# ESP32 register map
Vendor: ESPRESSIF SYSTEMS (SHANGHAI) CO., LTD.; Series: ESP32 Series; File version: 17
CPU: Xtensa LX6 r0p0, little endian, no MPU, FPU, 0 interrupt priority bits
Address unit: 32 bits
Registers are 32-bit, read-write, reset 0x0 unless marked. A register's access mark holds for its fields unless they carry their own. Offsets are from the block's base; [hi:lo] are bit positions; {n}, {i} and the like mark numbered series.

## SPI0 — SPI (Serial Peripheral Interface) Controller 0
Base 0x3FF43000
Same registers: SPI1 0x3FF42000, SPI2 0x3FF64000, SPI3 0x3FF65000
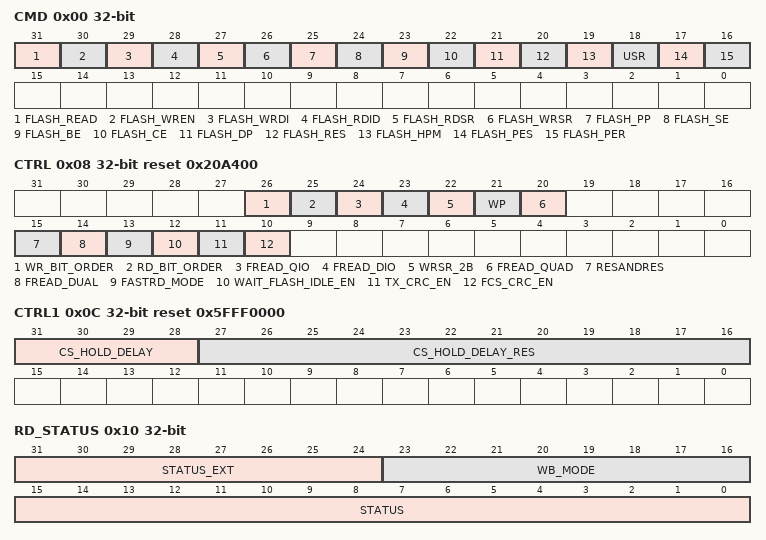
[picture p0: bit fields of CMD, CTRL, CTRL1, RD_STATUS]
0x00 CMD
  [31] FLASH_READ — Read flash enable. Read flash operation will be triggered when the bit is set. The bit will be cleared once the operation done. 1: enable 0: disable.
  [30] FLASH_WREN — Write flash enable. Write enable command will be sent when the bit is set. The bit will be cleared once the operation done. 1: enable 0: disable.
  [29] FLASH_WRDI — Write flash disable. Write disable command will be sent when the bit is set. The bit will be cleared once the operation done. 1: enable 0: disable.
  [28] FLASH_RDID — Read JEDEC ID . Read ID command will be sent when the bit is set. The bit will be cleared once the operation done. 1: enable 0: disable.
  [27] FLASH_RDSR — Read status register-1. Read status operation will be triggered when the bit is set. The bit will be cleared once the operation done.1: enable 0: disable.
  [26] FLASH_WRSR — Write status register enable. Write status operation will be triggered when the bit is set. The bit will be cleared once the operation done.1: enable 0: disable.
  [25] FLASH_PP — Page program enable(1 byte ~256 bytes data to be programmed). Page program operation will be triggered when the bit is set. The bit will be cleared once the operation done .1: enable 0: disable.
  [24] FLASH_SE — Sector erase enable. A 4KB sector is erased via SPI command 20H. Sector erase operation will be triggered when the bit is set. The bit will be cleared once the operation done.1: enable 0: disable.
  [23] FLASH_BE — Block erase enable. A 64KB block is erased via SPI command D8H. Block erase operation will be triggered when the bit is set. The bit will be cleared once the operation done.1: enable 0: disable.
  [22] FLASH_CE — Chip erase enable. Chip erase operation will be triggered when the bit is set. The bit will be cleared once the operation done.1: enable 0: disable.
  [21] FLASH_DP — Drive Flash into power down. An operation will be triggered when the bit is set. The bit will be cleared once the operation done.1: enable 0: disable.
  [20] FLASH_RES — This bit combined with reg_resandres bit releases Flash from the power-down state or high performance mode and obtains the devices ID. The bit will be cleared once the operation done.1: enable 0: disable.
  [19] FLASH_HPM — Drive Flash into high performance mode. The bit will be cleared once the operation done.1: enable 0: disable.
  [18] USR — User define command enable. An operation will be triggered when the bit is set. The bit will be cleared once the operation done.1: enable 0: disable.
  [17] FLASH_PES — program erase suspend bit program erase suspend operation will be triggered when the bit is set. The bit will be cleared once the operation done.1: enable 0: disable.
  [16] FLASH_PER — program erase resume bit program erase suspend operation will be triggered when the bit is set. The bit will be cleared once the operation done.1: enable 0: disable.
0x04 ADDR access not given
0x08 CTRL reset 0x20A400
  [26] WR_BIT_ORDER — In command address write-data (MOSI) phases 1: LSB firs 0: MSB first
  [25] RD_BIT_ORDER — In read-data (MISO) phase 1: LSB first 0: MSB first
  [24] FREAD_QIO — In the read operations address phase and read-data phase apply 4 signals. 1: enable 0: disable.
  [23] FREAD_DIO — In the read operations address phase and read-data phase apply 2 signals. 1: enable 0: disable.
  [22] WRSR_2B — two bytes data will be written to status register when it is set. 1: enable 0: disable.
  [21] WP — Write protect signal output when SPI is idle. 1: output high 0: output low.
  [20] FREAD_QUAD — In the read operations read-data phase apply 4 signals. 1: enable 0: disable.
  [15] RESANDRES — The Device ID is read out to SPI_RD_STATUS register, this bit combine with spi_flash_res bit. 1: enable 0: disable.
  [14] FREAD_DUAL — In the read operations read-data phase apply 2 signals. 1: enable 0: disable.
  [13] FASTRD_MODE — This bit enable the bits: spi_fread_qio spi_fread_dio spi_fread_qout and spi_fread_dout. 1: enable 0: disable.
  [12] WAIT_FLASH_IDLE_EN — wait flash idle when program flash or erase flash. 1: enable 0: disable.
  [11] TX_CRC_EN — For SPI1 enable crc32 when writing encrypted data to flash. 1: enable 0:disable
  [10] FCS_CRC_EN — For SPI1 initialize crc32 module before writing encrypted data to flash. Active low.
0x0C CTRL1 reset 0x5FFF0000
  [31:28] CS_HOLD_DELAY — SPI cs signal is delayed by spi clock cycles
  [27:16] CS_HOLD_DELAY_RES — Delay cycles of resume Flash when resume Flash is enable by spi clock.
0x10 RD_STATUS
  [31:24] STATUS_EXT — In the slave mode,it is the status for master to read out.
  [23:16] WB_MODE — Mode bits in the flash fast read mode, it is combined with spi_fastrd_mode bit.
  [15:0] STATUS — In the slave mode, it is the status for master to read out.
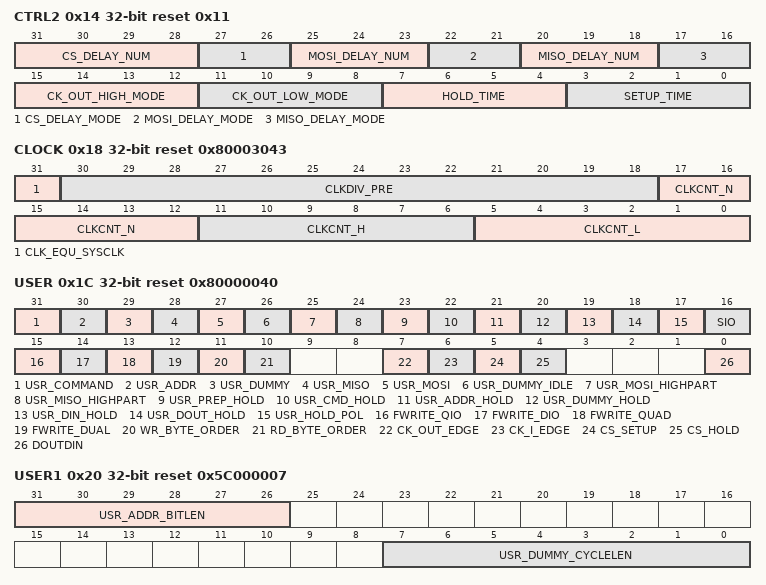
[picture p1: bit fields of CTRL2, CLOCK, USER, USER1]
0x14 CTRL2 reset 0x11
  [31:28] CS_DELAY_NUM — spi_cs signal is delayed by system clock cycles
  [27:26] CS_DELAY_MODE — spi_cs signal is delayed by spi_clk . 0: zero 1: if spi_ck_out_edge or spi_ck_i_edge is set 1 delayed by half cycle else delayed by one cycle 2: if spi_ck_out_edge or spi_ck_i_edge is set 1 delayed by one cycle else delayed by half cycle 3: delayed one cycle
  [25:23] MOSI_DELAY_NUM — MOSI signals are delayed by system clock cycles
  [22:21] MOSI_DELAY_MODE — MOSI signals are delayed by spi_clk. 0: zero 1: if spi_ck_out_edge or spi_ck_i_edge is set 1 delayed by half cycle else delayed by one cycle 2: if spi_ck_out_edge or spi_ck_i_edge is set 1 delayed by one cycle else delayed by half cycle 3: delayed one cycle
  [20:18] MISO_DELAY_NUM — MISO signals are delayed by system clock cycles
  [17:16] MISO_DELAY_MODE — MISO signals are delayed by spi_clk. 0: zero 1: if spi_ck_out_edge or spi_ck_i_edge is set 1 delayed by half cycle else delayed by one cycle 2: if spi_ck_out_edge or spi_ck_i_edge is set 1 delayed by one cycle else delayed by half cycle 3: delayed one cycle
  [15:12] CK_OUT_HIGH_MODE — modify spi clock duty ratio when the value is lager than 8, the bits are combined with spi_clkcnt_N bits and spi_clkcnt_H bits.
  [11:8] CK_OUT_LOW_MODE — modify spi clock duty ratio when the value is lager than 8, the bits are combined with spi_clkcnt_N bits and spi_clkcnt_L bits.
  [7:4] HOLD_TIME — delay cycles of cs pin by spi clock, this bits combined with spi_cs_hold bit.
  [3:0] SETUP_TIME — (cycles-1) of ¡°prepare¡± phase by spi clock, this bits combined with spi_cs_setup bit.
0x18 CLOCK reset 0x80003043
  [31] CLK_EQU_SYSCLK — In the master mode 1: spi_clk is eqaul to system 0: spi_clk is divided from system clock.
  [30:18] CLKDIV_PRE — In the master mode it is pre-divider of spi_clk.
  [17:12] CLKCNT_N — In the master mode it is the divider of spi_clk. So spi_clk frequency is system/(spi_clkdiv_pre+1)/(spi_clkcnt_N+1)
  [11:6] CLKCNT_H — In the master mode it must be floor((spi_clkcnt_N+1)/2-1). In the slave mode it must be 0.
  [5:0] CLKCNT_L — In the master mode it must be equal to spi_clkcnt_N. In the slave mode it must be 0.
0x1C USER reset 0x80000040
  [31] USR_COMMAND — This bit enable the command phase of an operation.
  [30] USR_ADDR — This bit enable the address phase of an operation.
  [29] USR_DUMMY — This bit enable the dummy phase of an operation.
  [28] USR_MISO — This bit enable the read-data phase of an operation.
  [27] USR_MOSI — This bit enable the write-data phase of an operation.
  [26] USR_DUMMY_IDLE — spi clock is disable in dummy phase when the bit is enable.
  [25] USR_MOSI_HIGHPART — write-data phase only access to high-part of the buffer spi_w8~spi_w15. 1: enable 0: disable.
  [24] USR_MISO_HIGHPART — read-data phase only access to high-part of the buffer spi_w8~spi_w15. 1: enable 0: disable.
  [23] USR_PREP_HOLD — spi is hold at prepare state the bit combined with spi_usr_hold_pol bit.
  [22] USR_CMD_HOLD — spi is hold at command state the bit combined with spi_usr_hold_pol bit.
  [21] USR_ADDR_HOLD — spi is hold at address state the bit combined with spi_usr_hold_pol bit.
  [20] USR_DUMMY_HOLD — spi is hold at dummy state the bit combined with spi_usr_hold_pol bit.
  [19] USR_DIN_HOLD — spi is hold at data in state the bit combined with spi_usr_hold_pol bit.
  [18] USR_DOUT_HOLD — spi is hold at data out state the bit combined with spi_usr_hold_pol bit.
  [17] USR_HOLD_POL — It is combined with hold bits to set the polarity of spi hold line 1: spi will be held when spi hold line is high 0: spi will be held when spi hold line is low
  [16] SIO — Set the bit to enable 3-line half duplex communication mosi and miso signals share the same pin. 1: enable 0: disable.
  [15] FWRITE_QIO — In the write operations address phase and read-data phase apply 4 signals.
  [14] FWRITE_DIO — In the write operations address phase and read-data phase apply 2 signals.
  [13] FWRITE_QUAD — In the write operations read-data phase apply 4 signals
  [12] FWRITE_DUAL — In the write operations read-data phase apply 2 signals
  [11] WR_BYTE_ORDER — In command address write-data (MOSI) phases 1: big-endian 0: litte_endian
  [10] RD_BYTE_ORDER — In read-data (MISO) phase 1: big-endian 0: little_endian
  [7] CK_OUT_EDGE — the bit combined with spi_mosi_delay_mode bits to set mosi signal delay mode.
  [6] CK_I_EDGE — In the slave mode the bit is same as spi_ck_out_edge in master mode. It is combined with spi_miso_delay_mode bits.
  [5] CS_SETUP — spi cs is enable when spi is in ¡°prepare¡± phase. 1: enable 0: disable.
  [4] CS_HOLD — spi cs keep low when spi is in ¡°done¡± phase. 1: enable 0: disable.
  [0] DOUTDIN — Set the bit to enable full duplex communication. 1: enable 0: disable.
0x20 USER1 reset 0x5C000007
  [31:26] USR_ADDR_BITLEN — The length in bits of address phase. The register value shall be (bit_num-1).
  [7:0] USR_DUMMY_CYCLELEN — The length in spi_clk cycles of dummy phase. The register value shall be (cycle_num-1).
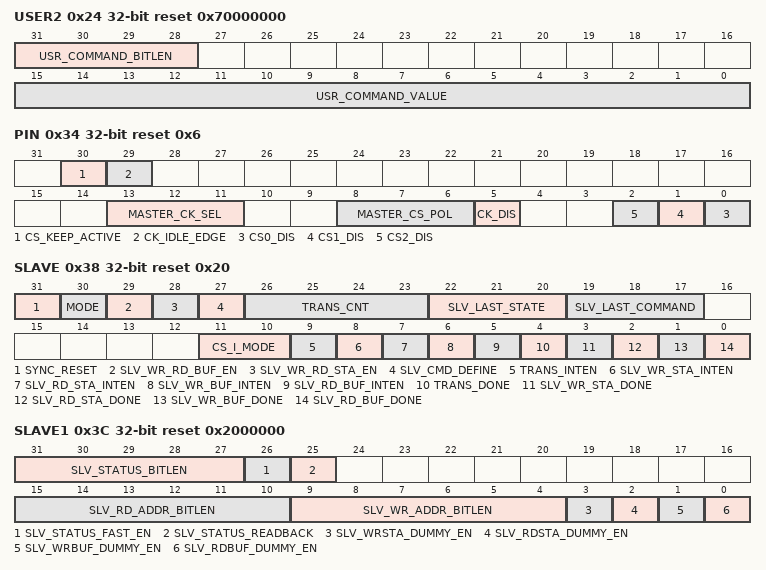
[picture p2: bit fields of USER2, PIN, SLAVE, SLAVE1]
0x24 USER2 reset 0x70000000
  [31:28] USR_COMMAND_BITLEN — The length in bits of command phase. The register value shall be (bit_num-1)
  [15:0] USR_COMMAND_VALUE — The value of command.
0x28 MOSI_DLEN
  [23:0] USR_MOSI_DBITLEN — The length in bits of write-data. The register value shall be (bit_num-1).
0x2C MISO_DLEN
  [23:0] USR_MISO_DBITLEN — The length in bits of read-data. The register value shall be (bit_num-1).
0x30 SLV_WR_STATUS
  [31:0] SLV_WR_ST — In the slave mode this register are the status register for the master to write into. In the master mode this register are the higher 32bits in the 64 bits address condition.
0x34 PIN reset 0x6
  [30] CS_KEEP_ACTIVE — spi cs line keep low when the bit is set.
  [29] CK_IDLE_EDGE — 1: spi clk line is high when idle 0: spi clk line is low when idle
  [13:11] MASTER_CK_SEL — In the master mode spi cs line is enable as spi clk it is combined with spi_cs0_dis spi_cs1_dis spi_cs2_dis.
  [8:6] MASTER_CS_POL — In the master mode the bits are the polarity of spi cs line the value is equivalent to spi_cs ^ spi_master_cs_pol.
  [5] CK_DIS — 1: spi clk out disable 0: spi clk out enable
  [n] CS{n}_DIS (n=0..2) — Set this bit to raise high SPI_CS{n} pin, which means that the SPI device(Ext_RAM(0)/flash(1)) connected to SPI_CS{n} is in low level when SPI1 transfer starts
0x38 SLAVE access not given reset 0x20
  [31] SYNC_RESET rw — Software reset enable, reset the spi clock line cs line and data lines.
  [30] MODE rw — 1: slave mode 0: master mode.
  [29] SLV_WR_RD_BUF_EN rw — write and read buffer enable in the slave mode
  [28] SLV_WR_RD_STA_EN rw — write and read status enable in the slave mode
  [27] SLV_CMD_DEFINE rw — 1: slave mode commands are defined in SPI_SLAVE3. 0: slave mode commands are fixed as: 1: write-status 2: write-buffer and 3: read-buffer.
  [26:23] TRANS_CNT ro — The operations counter in both the master mode and the slave mode. 4: read-status
  [22:20] SLV_LAST_STATE ro — In the slave mode it is the state of spi state machine.
  [19:17] SLV_LAST_COMMAND ro — In the slave mode it is the value of command.
  [11:10] CS_I_MODE rw — In the slave mode this bits used to synchronize the input spi cs signal and eliminate spi cs jitter.
  [9] TRANS_INTEN — The interrupt enable bit for the SPI_TRANS_DONE_INT interrupt.
  [8] SLV_WR_STA_INTEN — The interrupt enable bit for the SPI_SLV_WR_STA_INT interrupt.
  [7] SLV_RD_STA_INTEN — The interrupt enable bit for the SPI_SLV_RD_STA_INT interrupt.
  [6] SLV_WR_BUF_INTEN — The interrupt enable bit for the SPI_SLV_WR_BUF_INT interrupt.
  [5] SLV_RD_BUF_INTEN — The interrupt enable bit for the SPI_SLV_RD_BUF_INT interrupt.
  [4] TRANS_DONE rw — The interrupt raw bit for the completion of any operation in both the master mode and the slave mode.
  [3] SLV_WR_STA_DONE rw — The interrupt raw bit for the completion of write-status operation in the slave mode.
  [2] SLV_RD_STA_DONE rw — The interrupt raw bit for the completion of read-status operation in the slave mode.
  [1] SLV_WR_BUF_DONE rw — The interrupt raw bit for the completion of write-buffer operation in the slave mode.
  [0] SLV_RD_BUF_DONE rw — The interrupt raw bit for the completion of read-buffer operation in the slave mode.
0x3C SLAVE1 reset 0x2000000
  [31:27] SLV_STATUS_BITLEN — In the slave mode it is the length of status bit.
  [26] SLV_STATUS_FAST_EN — In the slave mode enable fast read status.
  [25] SLV_STATUS_READBACK — In the slave mode 1:read register of SPI_SLV_WR_STATUS 0: read register of SPI_RD_STATUS.
  [15:10] SLV_RD_ADDR_BITLEN — In the slave mode it is the address length in bits for read-buffer operation. The register value shall be (bit_num-1).
  [9:4] SLV_WR_ADDR_BITLEN — In the slave mode it is the address length in bits for write-buffer operation. The register value shall be (bit_num-1).
  [3] SLV_WRSTA_DUMMY_EN — In the slave mode it is the enable bit of dummy phase for write-status operations.
  [2] SLV_RDSTA_DUMMY_EN — In the slave mode it is the enable bit of dummy phase for read-status operations.
  [1] SLV_WRBUF_DUMMY_EN — In the slave mode it is the enable bit of dummy phase for write-buffer operations.
  [0] SLV_RDBUF_DUMMY_EN — In the slave mode it is the enable bit of dummy phase for read-buffer operations.
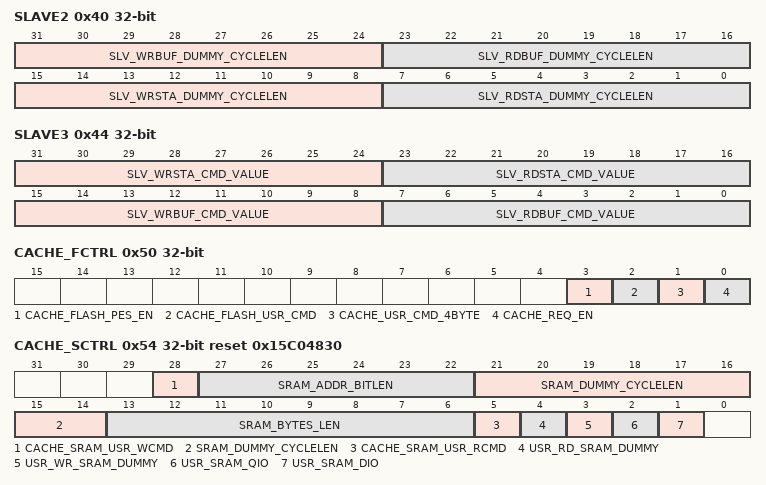
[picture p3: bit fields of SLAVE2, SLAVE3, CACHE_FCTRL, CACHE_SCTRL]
0x40 SLAVE2
  [31:24] SLV_WRBUF_DUMMY_CYCLELEN — In the slave mode it is the length in spi_clk cycles of dummy phase for write-buffer operations. The register value shall be (cycle_num-1).
  [23:16] SLV_RDBUF_DUMMY_CYCLELEN — In the slave mode it is the length in spi_clk cycles of dummy phase for read-buffer operations. The register value shall be (cycle_num-1).
  [15:8] SLV_WRSTA_DUMMY_CYCLELEN — In the slave mode it is the length in spi_clk cycles of dummy phase for write-status operations. The register value shall be (cycle_num-1).
  [7:0] SLV_RDSTA_DUMMY_CYCLELEN — In the slave mode it is the length in spi_clk cycles of dummy phase for read-status operations. The register value shall be (cycle_num-1).
0x44 SLAVE3
  [31:24] SLV_WRSTA_CMD_VALUE — In the slave mode it is the value of write-status command.
  [23:16] SLV_RDSTA_CMD_VALUE — In the slave mode it is the value of read-status command.
  [15:8] SLV_WRBUF_CMD_VALUE — In the slave mode it is the value of write-buffer command.
  [7:0] SLV_RDBUF_CMD_VALUE — In the slave mode it is the value of read-buffer command.
0x48 SLV_WRBUF_DLEN
  [23:0] SLV_WRBUF_DBITLEN — In the slave mode it is the length in bits for write-buffer operations. The register value shall be (bit_num-1).
0x4C SLV_RDBUF_DLEN
  [23:0] SLV_RDBUF_DBITLEN — In the slave mode it is the length in bits for read-buffer operations. The register value shall be (bit_num-1).
0x50 CACHE_FCTRL
  [3] CACHE_FLASH_PES_EN — For SPI0 spi1 send suspend command before cache read flash 1: enable 0:disable.
  [2] CACHE_FLASH_USR_CMD — For SPI0 cache read flash for user define command 1: enable 0:disable.
  [1] CACHE_USR_CMD_4BYTE — For SPI0 cache read flash with 4 bytes command 1: enable 0:disable.
  [0] CACHE_REQ_EN — For SPI0 Cache access enable 1: enable 0:disable.
0x54 CACHE_SCTRL reset 0x15C04830
  [28] CACHE_SRAM_USR_WCMD — For SPI0 In the spi sram mode cache write sram for user define command
  [27:22] SRAM_ADDR_BITLEN — For SPI0 In the sram mode it is the length in bits of address phase. The register value shall be (bit_num-1).
  [21:14] SRAM_DUMMY_CYCLELEN — For SPI0 In the sram mode it is the length in bits of address phase. The register value shall be (bit_num-1).
  [13:6] SRAM_BYTES_LEN — For SPI0 In the sram mode it is the byte length of spi read sram data.
  [5] CACHE_SRAM_USR_RCMD — For SPI0 In the spi sram mode cache read sram for user define command.
  [4] USR_RD_SRAM_DUMMY — For SPI0 In the spi sram mode it is the enable bit of dummy phase for read operations.
  [3] USR_WR_SRAM_DUMMY — For SPI0 In the spi sram mode it is the enable bit of dummy phase for write operations.
  [2] USR_SRAM_QIO — For SPI0 In the spi sram mode spi quad I/O mode enable 1: enable 0:disable
  [1] USR_SRAM_DIO — For SPI0 In the spi sram mode spi dual I/O mode enable 1: enable 0:disable
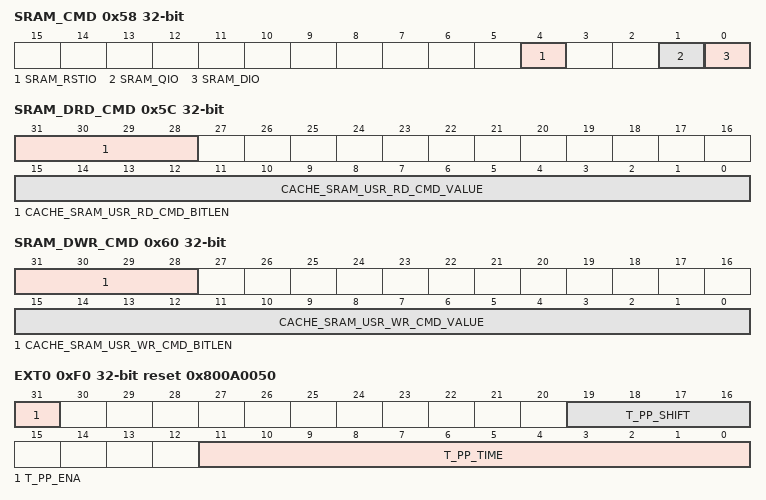
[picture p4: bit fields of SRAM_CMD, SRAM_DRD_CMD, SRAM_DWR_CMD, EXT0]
0x58 SRAM_CMD
  [4] SRAM_RSTIO — For SPI0 SRAM IO mode reset enable. SRAM IO mode reset operation will be triggered when the bit is set. The bit will be cleared once the operation done
  [1] SRAM_QIO — For SPI0 SRAM QIO mode enable . SRAM QIO enable command will be send when the bit is set. The bit will be cleared once the operation done.
  [0] SRAM_DIO — For SPI0 SRAM DIO mode enable . SRAM DIO enable command will be send when the bit is set. The bit will be cleared once the operation done.
0x5C SRAM_DRD_CMD
  [31:28] CACHE_SRAM_USR_RD_CMD_BITLEN — For SPI0 When cache mode is enable it is the length in bits of command phase for SRAM. The register value shall be (bit_num-1).
  [15:0] CACHE_SRAM_USR_RD_CMD_VALUE — For SPI0 When cache mode is enable it is the read command value of command phase for SRAM.
0x60 SRAM_DWR_CMD
  [31:28] CACHE_SRAM_USR_WR_CMD_BITLEN — For SPI0 When cache mode is enable it is the in bits of command phase for SRAM. The register value shall be (bit_num-1).
  [15:0] CACHE_SRAM_USR_WR_CMD_VALUE — For SPI0 When cache mode is enable it is the write command value of command phase for SRAM.
0x64 SLV_RD_BIT
  [23:0] SLV_RDATA_BIT — In the slave mode it is the bit length of read data. The value is the length - 1.
{0x80+4i} W{i} (i=0..15)
  [31:0] BUF — data buffer
0xC0 TX_CRC
  [31:0] DATA — For SPI1 the value of crc32 for 256 bits data.
0xF0 EXT0 reset 0x800A0050
  [31] T_PP_ENA — page program delay enable.
  [19:16] T_PP_SHIFT — page program delay time shift .
  [11:0] T_PP_TIME — page program delay time by system clock.
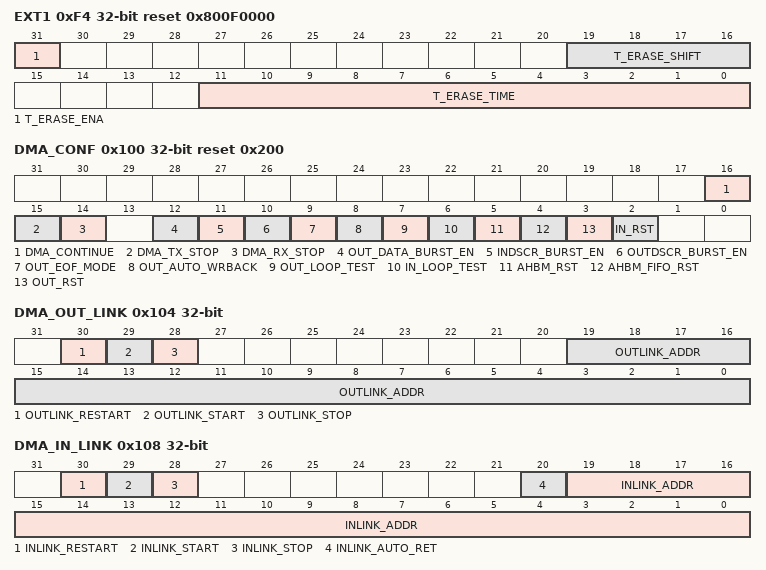
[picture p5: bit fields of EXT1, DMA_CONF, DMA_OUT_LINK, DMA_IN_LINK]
0xF4 EXT1 reset 0x800F0000
  [31] T_ERASE_ENA — erase flash delay enable.
  [19:16] T_ERASE_SHIFT — erase flash delay time shift.
  [11:0] T_ERASE_TIME — erase flash delay time by system clock.
0xF8 EXT2 ro
  [2:0] ST — The status of spi state machine .
0xFC EXT3
  [1:0] INT_HOLD_ENA — This register is for two SPI masters to share the same cs clock and data signals. The bits of one SPI are set if the other SPI is busy the SPI will be hold. 1(3): hold at ¡°idle¡± phase 2: hold at ¡°prepare¡± phase.
0x100 DMA_CONF reset 0x200
  [16] DMA_CONTINUE — spi dma continue tx/rx data.
  [15] DMA_TX_STOP — spi dma write data stop when in continue tx/rx mode.
  [14] DMA_RX_STOP — spi dma read data stop when in continue tx/rx mode.
  [12] OUT_DATA_BURST_EN — spi dma read data from memory in burst mode.
  [11] INDSCR_BURST_EN — read descriptor use burst mode when write data to memory.
  [10] OUTDSCR_BURST_EN — read descriptor use burst mode when read data for memory.
  [9] OUT_EOF_MODE — out eof flag generation mode . 1: when dma pop all data from fifo 0:when ahb push all data to fifo.
  [8] OUT_AUTO_WRBACK — when the link is empty jump to next automatically.
  [7] OUT_LOOP_TEST — Set bit to test out link.
  [6] IN_LOOP_TEST — Set bit to test in link.
  [5] AHBM_RST — reset spi dma ahb master.
  [4] AHBM_FIFO_RST — reset spi dma ahb master fifo pointer.
  [3] OUT_RST — The bit is used to reset out dma fsm and out data fifo pointer.
  [2] IN_RST — The bit is used to reset in dma fsm and in data fifo pointer.
0x104 DMA_OUT_LINK
  [30] OUTLINK_RESTART — Set the bit to mount on new outlink descriptors.
  [29] OUTLINK_START — Set the bit to start to use outlink descriptor.
  [28] OUTLINK_STOP — Set the bit to stop to use outlink descriptor.
  [19:0] OUTLINK_ADDR — The address of the first outlink descriptor.
0x108 DMA_IN_LINK
  [30] INLINK_RESTART — Set the bit to mount on new inlink descriptors.
  [29] INLINK_START — Set the bit to start to use inlink descriptor.
  [28] INLINK_STOP — Set the bit to stop to use inlink descriptor.
  [20] INLINK_AUTO_RET — when the bit is set inlink descriptor returns to the next descriptor while a packet is wrong
  [19:0] INLINK_ADDR — The address of the first inlink descriptor.
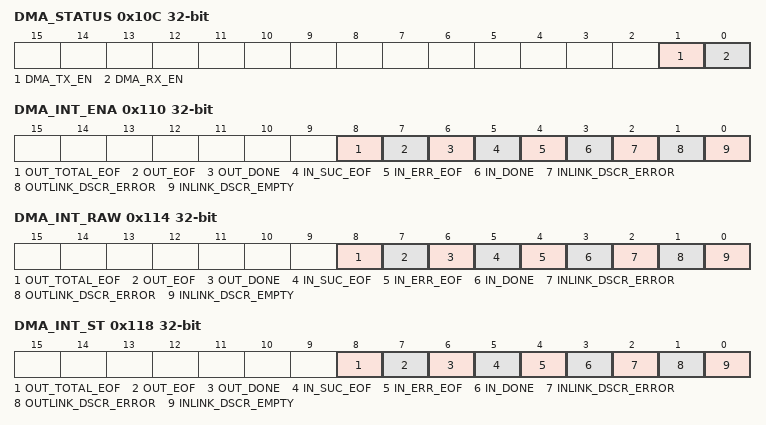
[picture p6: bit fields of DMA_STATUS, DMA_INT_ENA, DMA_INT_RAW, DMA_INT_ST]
0x10C DMA_STATUS ro
  [1] DMA_TX_EN — spi dma write data status bit.
  [0] DMA_RX_EN — spi dma read data status bit.
0x110 DMA_INT_ENA
  [8] OUT_TOTAL_EOF — The enable bit for sending all the packets to host done.
  [7] OUT_EOF — The enable bit for sending a packet to host done.
  [6] OUT_DONE — The enable bit for completing usage of a outlink descriptor .
  [5] IN_SUC_EOF — The enable bit for completing receiving all the packets from host.
  [4] IN_ERR_EOF — The enable bit for receiving error.
  [3] IN_DONE — The enable bit for completing usage of a inlink descriptor.
  [2] INLINK_DSCR_ERROR — The enable bit for inlink descriptor error.
  [1] OUTLINK_DSCR_ERROR — The enable bit for outlink descriptor error.
  [0] INLINK_DSCR_EMPTY — The enable bit for lack of enough inlink descriptors.
0x114 DMA_INT_RAW ro
  [8] OUT_TOTAL_EOF — The raw bit for sending all the packets to host done.
  [7] OUT_EOF — The raw bit for sending a packet to host done.
  [6] OUT_DONE — The raw bit for completing usage of a outlink descriptor.
  [5] IN_SUC_EOF — The raw bit for completing receiving all the packets from host.
  [4] IN_ERR_EOF — The raw bit for receiving error.
  [3] IN_DONE — The raw bit for completing usage of a inlink descriptor.
  [2] INLINK_DSCR_ERROR — The raw bit for inlink descriptor error.
  [1] OUTLINK_DSCR_ERROR — The raw bit for outlink descriptor error.
  [0] INLINK_DSCR_EMPTY — The raw bit for lack of enough inlink descriptors.
0x118 DMA_INT_ST ro
  [8] OUT_TOTAL_EOF — The status bit for sending all the packets to host done.
  [7] OUT_EOF — The status bit for sending a packet to host done.
  [6] OUT_DONE — The status bit for completing usage of a outlink descriptor.
  [5] IN_SUC_EOF — The status bit for completing receiving all the packets from host.
  [4] IN_ERR_EOF — The status bit for receiving error.
  [3] IN_DONE — The status bit for completing usage of a inlink descriptor.
  [2] INLINK_DSCR_ERROR — The status bit for inlink descriptor error.
  [1] OUTLINK_DSCR_ERROR — The status bit for outlink descriptor error.
  [0] INLINK_DSCR_EMPTY — The status bit for lack of enough inlink descriptors.
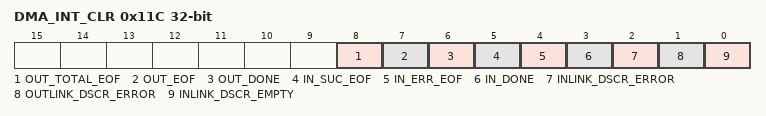
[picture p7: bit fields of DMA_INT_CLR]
0x11C DMA_INT_CLR
  [8] OUT_TOTAL_EOF write-1-clears — The clear bit for sending all the packets to host done.
  [7] OUT_EOF write-1-clears — The clear bit for sending a packet to host done.
  [6] OUT_DONE write-1-clears — The clear bit for completing usage of a outlink descriptor.
  [5] IN_SUC_EOF write-1-clears — The clear bit for completing receiving all the packets from host.
  [4] IN_ERR_EOF write-1-clears — The clear bit for receiving error.
  [3] IN_DONE write-1-clears — The clear bit for completing usage of a inlink descriptor.
  [2] INLINK_DSCR_ERROR write-1-clears — The clear bit for inlink descriptor error.
  [1] OUTLINK_DSCR_ERROR write-1-clears — The clear bit for outlink descriptor error.
  [0] INLINK_DSCR_EMPTY write-1-clears — The clear bit for lack of enough inlink descriptors.
0x120 IN_ERR_EOF_DES_ADDR ro
  [31:0] DMA_IN_ERR_EOF_DES_ADDR — The inlink descriptor address when spi dma produce receiving error.
0x124 IN_SUC_EOF_DES_ADDR ro
  [31:0] DMA_IN_SUC_EOF_DES_ADDR — The last inlink descriptor address when spi dma produce from_suc_eof.
0x128 INLINK_DSCR ro
  [31:0] DMA_INLINK_DSCR — The content of current in descriptor pointer.
0x12C INLINK_DSCR_BF0 ro
  [31:0] DMA_INLINK_DSCR_BF0 — The content of next in descriptor pointer.
0x130 INLINK_DSCR_BF1 ro
  [31:0] DMA_INLINK_DSCR_BF1 — The content of current in descriptor data buffer pointer.
0x134 OUT_EOF_BFR_DES_ADDR ro
  [31:0] DMA_OUT_EOF_BFR_DES_ADDR — The address of buffer relative to the outlink descriptor that produce eof.
0x138 OUT_EOF_DES_ADDR ro
  [31:0] DMA_OUT_EOF_DES_ADDR — The last outlink descriptor address when spi dma produce to_eof.
0x13C OUTLINK_DSCR ro
  [31:0] DMA_OUTLINK_DSCR — The content of current out descriptor pointer.
0x140 OUTLINK_DSCR_BF0 ro
  [31:0] DMA_OUTLINK_DSCR_BF0 — The content of next out descriptor pointer.
0x144 OUTLINK_DSCR_BF1 ro
  [31:0] DMA_OUTLINK_DSCR_BF1 — The content of current out descriptor data buffer pointer.
0x148 DMA_RSTATUS ro
  [31:0] DMA_OUT_STATUS — spi dma read data from memory status.
0x14C DMA_TSTATUS ro
  [31:0] DMA_IN_STATUS — spi dma write data to memory status.
0x3FC DATE
